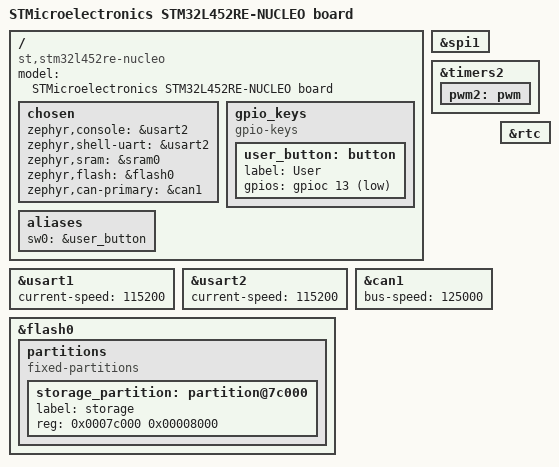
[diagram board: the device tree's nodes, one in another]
/*
 * Copyright (c) 2019 Libre Solar Technologies GmbH
 * Copyright (c) 2020 Sparks, Circuits and Robotics SL
 *
 * SPDX-License-Identifier: Apache-2.0
 */

/dts-v1/;
#include <st/l4/stm32l452Xe.dtsi>
#include "arduino_r3_connector.dtsi"

/ {
	model = "STMicroelectronics STM32L452RE-NUCLEO board";
	compatible = "st,stm32l452re-nucleo", "st,stm32l452";

	chosen {
		zephyr,console = &usart2;
		zephyr,shell-uart = &usart2;
		zephyr,sram = &sram0;
		zephyr,flash = &flash0;
		zephyr,can-primary = &can1;
	};

	gpio_keys {
		compatible = "gpio-keys";
		user_button: button {
			label = "User";
			gpios = <&gpioc 13 GPIO_ACTIVE_LOW>;
		};
	};

	aliases {
		sw0 = &user_button;
	};
};

&usart1 {
	current-speed = <115200>;
};

&usart2 {
	current-speed = <115200>;
	status = "okay";
};

&spi1 {
	status = "okay";
};

&timers2 {
	status = "okay";

	pwm2: pwm {
		status = "okay";
	};
};

&can1 {
	bus-speed = <125000>;
	status = "okay";
};

&rtc {
	status = "okay";
};

&flash0 {
	/*
	 * For more information, see:
	 * http://docs.zephyrproject.org/latest/guides/dts/index.html#flash-partitions
	 */
	partitions {
		compatible = "fixed-partitions";
		#address-cells = <1>;
		#size-cells = <1>;
		/*
		 * Reserve the final 16 KiB for file system partition
		 */
		storage_partition: partition@7c000 {
			label = "storage";
			reg = <0x0007c000 0x00008000>;
		};
	};
};
